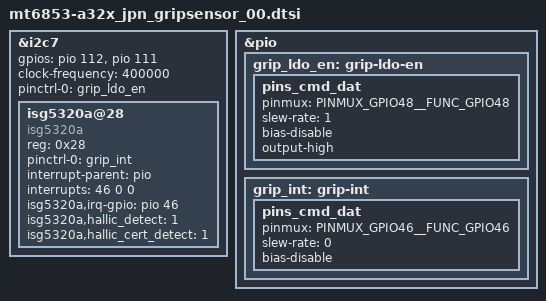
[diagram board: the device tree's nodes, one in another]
/*
 * SAMSUNG board device tree source
 *
 * Copyright (c) 2019 Samsung Electronics Co., Ltd.
 *		http://www.samsung.com
 *
 * This program is free software; you can redistribute it and/or modify
 * it under the terms of the GNU General Public License version 2 as
 * published by the Free Software Foundation.
 */

&i2c7 {
	gpios = <&pio 112 0 /* sda */
			&pio 111 0>; /* scl */
	#address-cells = <1>;
	#size-cells = <0>;
	status = "okay";
	clock-frequency = <400000>;
	pinctrl-names = "default";
	pinctrl-0 = <&grip_ldo_en>;
	isg5320a@28 {
		compatible = "isg5320a";
		reg = <0x28>;
		pinctrl-names = "default";
		pinctrl-0 = <&grip_int>;
		interrupt-parent = <&pio>;
		interrupts = <46 0 0>;
		isg5320a,irq-gpio = <&pio 46 0>;
		isg5320a,hallic_detect = <1>;
		isg5320a,hallic_cert_detect = <1>;
	};
};

&pio {
	grip_ldo_en: grip-ldo-en {
		pins_cmd_dat {
			pinmux = <PINMUX_GPIO48__FUNC_GPIO48>;
			slew-rate = <1>;
			bias-disable;
			output-high;
		};
	};

	grip_int: grip-int {
		pins_cmd_dat {
			pinmux = <PINMUX_GPIO46__FUNC_GPIO46>;
			slew-rate = <0>;
			bias-disable;
		};
	};
};

